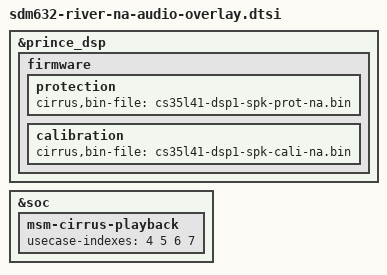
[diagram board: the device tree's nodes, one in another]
/* Copyright (c) 2018, The Linux Foundation. All rights reserved.
 *
 * This program is free software; you can redistribute it and/or modify
 * it under the terms of the GNU General Public License version 2 and
 * only version 2 as published by the Free Software Foundation.
 *
 * This program is distributed in the hope that it will be useful,
 * but WITHOUT ANY WARRANTY; without even the implied warranty of
 * MERCHANTABILITY or FITNESS FOR A PARTICULAR PURPOSE.  See the
 * GNU General Public License for more details.
 */

&prince_dsp {
	firmware {
		protection {
			cirrus,bin-file = "cs35l41-dsp1-spk-prot-na.bin";
		};
		calibration {
			cirrus,bin-file = "cs35l41-dsp1-spk-cali-na.bin";
		};
	};
};

&soc {
	msm-cirrus-playback {
		usecase-indexes = <4 5 6 7>;
	};
};
